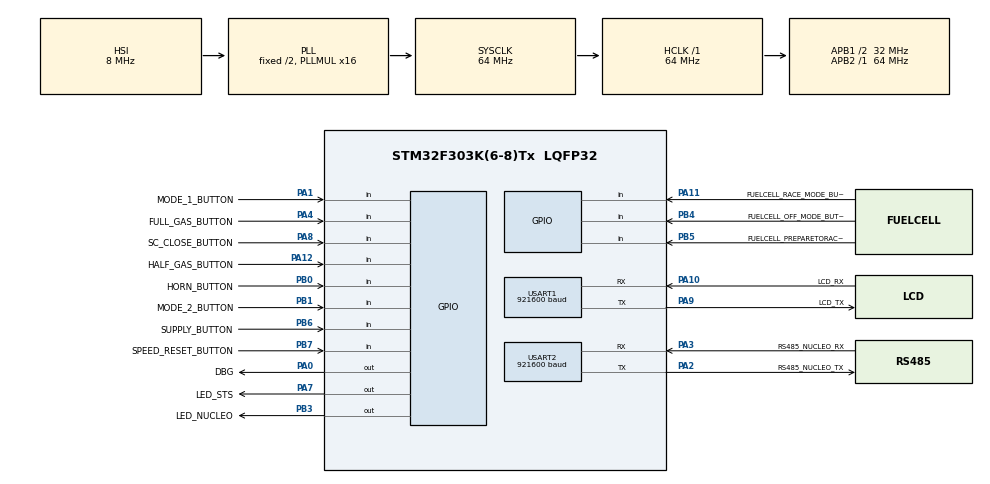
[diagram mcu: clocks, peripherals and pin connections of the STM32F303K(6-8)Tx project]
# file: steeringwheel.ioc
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CRC.CRCLength=CRC_POLYLENGTH_8B
CRC.DefaultInitValueUse=DEFAULT_INIT_VALUE_ENABLE
CRC.DefaultPolynomialUse=DEFAULT_POLYNOMIAL_DISABLE
Dma.Request0=USART1_TX
Dma.Request1=USART2_RX
Dma.USART1_TX.0.Direction=DMA_MEMORY_TO_PERIPH
Dma.USART1_TX.0.Instance=DMA1_Channel4
Dma.USART1_TX.0.MemDataAlignment=DMA_MDATAALIGN_BYTE
Dma.USART1_TX.0.MemInc=DMA_MINC_ENABLE
Dma.USART1_TX.0.Mode=DMA_NORMAL
Dma.USART1_TX.0.PeriphDataAlignment=DMA_PDATAALIGN_BYTE
Dma.USART1_TX.0.PeriphInc=DMA_PINC_DISABLE
Dma.USART1_TX.0.Priority=DMA_PRIORITY_LOW
Dma.USART2_RX.1.Direction=DMA_PERIPH_TO_MEMORY
Dma.USART2_RX.1.Instance=DMA1_Channel6
Dma.USART2_RX.1.MemDataAlignment=DMA_MDATAALIGN_BYTE
Dma.USART2_RX.1.MemInc=DMA_MINC_ENABLE
Dma.USART2_RX.1.Mode=DMA_NORMAL
Dma.USART2_RX.1.PeriphDataAlignment=DMA_PDATAALIGN_BYTE
Dma.USART2_RX.1.PeriphInc=DMA_PINC_DISABLE
Dma.USART2_RX.1.Priority=DMA_PRIORITY_HIGH
IWDG.Reload=1500
IWDG.Window=1500
Mcu.Family=STM32F3
Mcu.Name=STM32F303K(6-8)Tx
Mcu.Package=LQFP32
NVIC.DMA1_Channel4_IRQn=true\:2\:0\:true\:false\:true\:false\:true
NVIC.DMA1_Channel6_IRQn=true\:1\:0\:true\:false\:true\:false\:true
NVIC.PriorityGroup=NVIC_PRIORITYGROUP_2
NVIC.TIM6_DAC1_IRQn=true\:1\:1\:true\:false\:true\:true\:true
NVIC.TIM7_DAC2_IRQn=true\:3\:0\:true\:false\:true\:true\:true
NVIC.USART1_IRQn=true\:2\:0\:true\:false\:true\:true\:true
NVIC.USART2_IRQn=true\:1\:0\:true\:false\:true\:true\:true
PA0.GPIO_Label=DBG
PA0.Signal=GPIO_Output
PA1.GPIO_Label=MODE_1_BUTTON
PA1.Signal=GPIO_Input
PA10.GPIO_Label=LCD_RX
PA10.Mode=Asynchronous
PA10.Signal=USART1_RX
PA11.GPIO_Label=FUELCELL_RACE_MODE_BUTTON
PA11.Signal=GPIO_Input
PA12.GPIO_Label=HALF_GAS_BUTTON
PA12.Signal=GPIO_Input
PA2.GPIO_Label=RS485_NUCLEO_TX
PA2.Mode=Asynchronous
PA2.Signal=USART2_TX
PA3.GPIO_Label=RS485_NUCLEO_RX
PA3.Mode=Asynchronous
PA3.Signal=USART2_RX
PA4.GPIO_Label=FULL_GAS_BUTTON
PA4.Signal=GPIO_Input
PA7.GPIO_Label=LED_STS
PA7.Signal=GPIO_Output
PA8.GPIO_Label=SC_CLOSE_BUTTON
PA8.Signal=GPIO_Input
PA9.GPIO_Label=LCD_TX
PA9.Mode=Asynchronous
PA9.Signal=USART1_TX
PB0.GPIO_Label=HORN_BUTTON
PB0.Signal=GPIO_Input
PB1.GPIO_Label=MODE_2_BUTTON
PB1.Signal=GPIO_Input
PB3.GPIO_Label=LED_NUCLEO
PB3.Signal=GPIO_Output
PB4.GPIO_Label=FUELCELL_OFF_MODE_BUTTON
PB4.Signal=GPIO_Input
PB5.GPIO_Label=FUELCELL_PREPARETORACE_MODE_BUTTON
PB5.Signal=GPIO_Input
PB6.GPIO_Label=SUPPLY_BUTTON
PB6.GPIO_PuPd=GPIO_NOPULL
PB6.Signal=GPIO_Input
PB7.GPIO_Label=SPEED_RESET_BUTTON
PB7.Signal=GPIO_Input
ProjectManager.HeapSize=0x200
ProjectManager.StackSize=0x400
ProjectManager.TargetToolchain=STM32CubeIDE
RCC.AHBFreq_Value=64000000
RCC.APB1CLKDivider=RCC_HCLK_DIV2
RCC.APB1Freq_Value=32000000
RCC.APB1TimFreq_Value=64000000
RCC.APB2Freq_Value=64000000
RCC.APB2TimFreq_Value=64000000
RCC.CortexFreq_Value=64000000
RCC.HCLKFreq_Value=64000000
RCC.HSE_VALUE=8000000
RCC.HSI_VALUE=8000000
RCC.PLLMUL=RCC_PLL_MUL16
RCC.SYSCLKFreq_VALUE=64000000
RCC.SYSCLKSourceVirtual=RCC_SYSCLKSOURCE_PLLCLK
TIM6.Period=(100-1)
TIM6.Prescaler=(64-1)
TIM7.AutoReloadPreload=TIM_AUTORELOAD_PRELOAD_ENABLE
TIM7.Period=10-1
TIM7.Prescaler=64-1
USART1.BaudRate=921600
USART1.DMADisableonRxErrorParam=ADVFEATURE_DMA_DISABLEONRXERROR
USART1.Mode=MODE_TX_RX
USART1.OneBitSampling=UART_ONE_BIT_SAMPLE_ENABLE
USART1.OverSampling=UART_OVERSAMPLING_8
USART1.OverrunDisableParam=ADVFEATURE_OVERRUN_DISABLE
USART1.VirtualMode-Asynchronous=VM_ASYNC
USART2.BaudRate=921600
USART2.DMADisableonRxErrorParam=ADVFEATURE_DMA_DISABLEONRXERROR
USART2.OneBitSampling=UART_ONE_BIT_SAMPLE_ENABLE
USART2.OverSampling=UART_OVERSAMPLING_8
USART2.OverrunDisableParam=ADVFEATURE_OVERRUN_DISABLE
USART2.VirtualMode-Asynchronous=VM_ASYNC
VP_CRC_VS_CRC.Mode=CRC_Activate
VP_IWDG_VS_IWDG.Mode=IWDG_Activate
VP_TIM6_VS_ClockSourceINT.Mode=Enable_Timer
VP_TIM7_VS_ClockSourceINT.Mode=Enable_Timer
board=custom

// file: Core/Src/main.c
/* USER CODE BEGIN Header */
/**
  ******************************************************************************
  * @file           : main.c
  * @brief          : Main program body
  ******************************************************************************
  * @attention
  *
  * <h2><center>&copy; Copyright (c) 2020 STMicroelectronics.
  * All rights reserved.</center></h2>
  *
  * This software component is licensed by ST under BSD 3-Clause license,
  * the "License"; You may not use this file except in compliance with the
  * License. You may obtain a copy of the License at:
  *                        opensource.org/licenses/BSD-3-Clause
  *
  ******************************************************************************
  */
/* USER CODE END Header */
#include "main.h"
#include "crc.h"
#include "dma.h"
#include "iwdg.h"
#include "tim.h"
#include "usart.h"
#include "gpio.h"

/* USER CODE BEGIN Includes */
#include "hydrogreen.h"
/* USER CODE END Includes */

void SystemClock_Config(void);

int main(void)
{

  /* MCU Configuration--------------------------------------------------------*/

  /* Reset of all peripherals, Initializes the Flash interface and the Systick. */
  HAL_Init();

  /* Configure the system clock */
  SystemClock_Config();

  /* Initialize all configured peripherals */
  MX_GPIO_Init();
  MX_DMA_Init();
  MX_USART1_UART_Init();
  MX_USART2_UART_Init();
  MX_IWDG_Init();
  MX_CRC_Init();
  MX_TIM6_Init();
  MX_TIM7_Init();
  /* USER CODE BEGIN 2 */
  hydrogreen_main();
  /* USER CODE END 2 */

  /* Infinite loop */
  while (1)
  {

  }
}

void SystemClock_Config(void)
{
  RCC_OscInitTypeDef RCC_OscInitStruct = {0};
  RCC_ClkInitTypeDef RCC_ClkInitStruct = {0};
  RCC_PeriphCLKInitTypeDef PeriphClkInit = {0};

  /** Initializes the RCC Oscillators according to the specified parameters
  * in the RCC_OscInitTypeDef structure.
  */
  RCC_OscInitStruct.OscillatorType = RCC_OSCILLATORTYPE_HSI|RCC_OSCILLATORTYPE_LSI;
  RCC_OscInitStruct.HSIState = RCC_HSI_ON;
  RCC_OscInitStruct.HSICalibrationValue = RCC_HSICALIBRATION_DEFAULT;
  RCC_OscInitStruct.LSIState = RCC_LSI_ON;
  RCC_OscInitStruct.PLL.PLLState = RCC_PLL_ON;
  RCC_OscInitStruct.PLL.PLLSource = RCC_PLLSOURCE_HSI;
  RCC_OscInitStruct.PLL.PLLMUL = RCC_PLL_MUL16;
  if (HAL_RCC_OscConfig(&RCC_OscInitStruct) != HAL_OK)
  {
    Error_Handler();
  }
  /** Initializes the CPU, AHB and APB buses clocks
  */
  RCC_ClkInitStruct.ClockType = RCC_CLOCKTYPE_HCLK|RCC_CLOCKTYPE_SYSCLK
                              |RCC_CLOCKTYPE_PCLK1|RCC_CLOCKTYPE_PCLK2;
  RCC_ClkInitStruct.SYSCLKSource = RCC_SYSCLKSOURCE_PLLCLK;
  RCC_ClkInitStruct.AHBCLKDivider = RCC_SYSCLK_DIV1;
  RCC_ClkInitStruct.APB1CLKDivider = RCC_HCLK_DIV2;
  RCC_ClkInitStruct.APB2CLKDivider = RCC_HCLK_DIV1;

  if (HAL_RCC_ClockConfig(&RCC_ClkInitStruct, FLASH_LATENCY_2) != HAL_OK)
  {
    Error_Handler();
  }
  PeriphClkInit.PeriphClockSelection = RCC_PERIPHCLK_USART1;
  PeriphClkInit.Usart1ClockSelection = RCC_USART1CLKSOURCE_PCLK1;
  if (HAL_RCCEx_PeriphCLKConfig(&PeriphClkInit) != HAL_OK)
  {
    Error_Handler();
  }
}

void Error_Handler(void)
{
  /* USER CODE BEGIN Error_Handler_Debug */
  hydrogreen_hardFault();
  /* User can add his own implementation to report the HAL error return state */

  /* USER CODE END Error_Handler_Debug */
}

/************************ (C) COPYRIGHT STMicroelectronics *****END OF FILE****/
